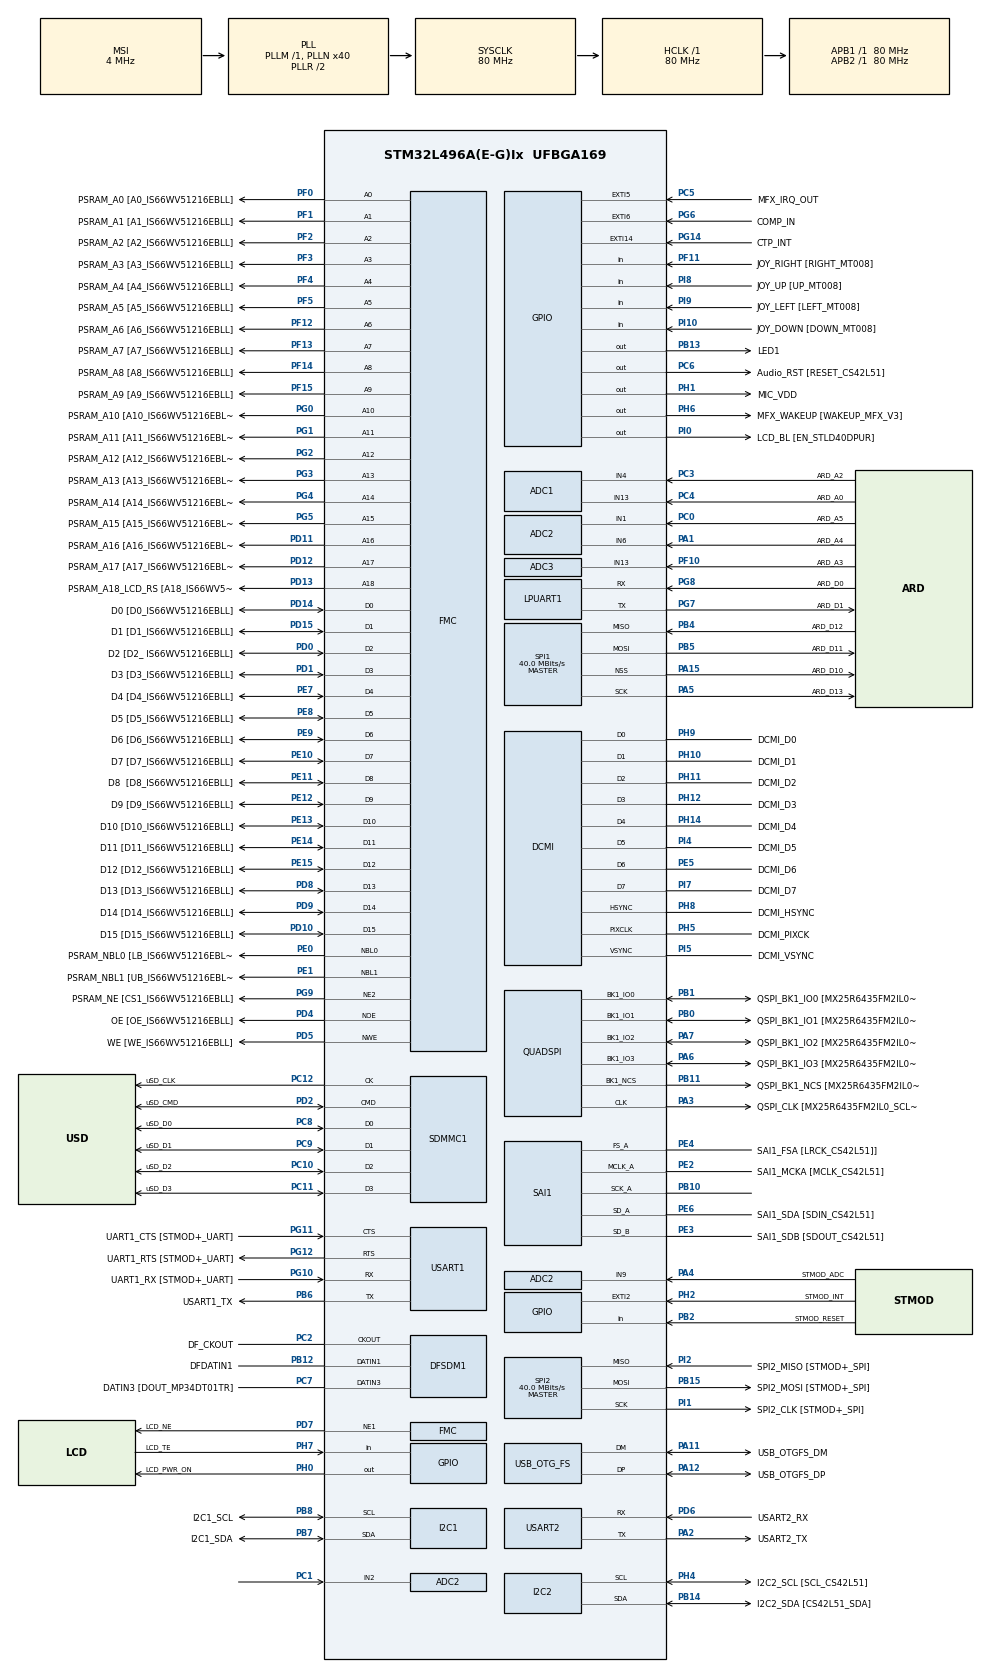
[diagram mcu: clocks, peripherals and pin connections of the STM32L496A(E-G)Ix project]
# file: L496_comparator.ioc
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ADC1.Channel-0\#ChannelRegularConversion=ADC_CHANNEL_4
ADC1.NbrOfConversionFlag=1
ADC1.OffsetNumber-0\#ChannelRegularConversion=ADC_OFFSET_NONE
ADC1.Rank-0\#ChannelRegularConversion=1
ADC1.SamplingTime-0\#ChannelRegularConversion=ADC_SAMPLETIME_2CYCLES_5
ADC1.master=1
ADC2.Channel-0\#ChannelRegularConversion=ADC_CHANNEL_9
ADC2.NbrOfConversionFlag=1
ADC2.OffsetNumber-0\#ChannelRegularConversion=ADC_OFFSET_NONE
ADC2.Rank-0\#ChannelRegularConversion=1
ADC2.SamplingTime-0\#ChannelRegularConversion=ADC_SAMPLETIME_2CYCLES_5
ADC3.Channel-0\#ChannelRegularConversion=ADC_CHANNEL_13
ADC3.NbrOfConversionFlag=1
ADC3.OffsetNumber-0\#ChannelRegularConversion=ADC_OFFSET_NONE
ADC3.Rank-0\#ChannelRegularConversion=1
ADC3.SamplingTime-0\#ChannelRegularConversion=ADC_SAMPLETIME_2CYCLES_5
DCMI.JPEGMode=DCMI_JPEG_DISABLE
I2C1.Timing=0x10909CEC
I2C2.Timing=0x10909CEC
Mcu.Family=STM32L4
Mcu.Name=STM32L496A(E-G)Ix
Mcu.Package=UFBGA169
NVIC.EXTI9_5_IRQn=true\:0\:0\:false\:false\:true\:true\:true
NVIC.OTG_FS_IRQn=true\:0\:0\:false\:false\:true\:true\:true
NVIC.PriorityGroup=NVIC_PRIORITYGROUP_4
NVIC.TIM2_IRQn=true\:0\:0\:false\:false\:true\:true\:true
PA0.GPIO_Label=STMOD_PWM
PA0.Mode=SYS_WakeUp0
PA0.Signal=SYS_WKUP1
PA1.GPIO_Label=ARD_A4
PA1.Signal=ADCx_IN6
PA10.GPIO_Label=USB_OTGFS_ID
PA10.Signal=USB_OTG_FS_ID
PA11.GPIO_Label=USB_OTGFS_DM
PA11.Mode=Device_Only
PA11.Signal=USB_OTG_FS_DM
PA12.GPIO_Label=USB_OTGFS_DP
PA12.Mode=Device_Only
PA12.Signal=USB_OTG_FS_DP
PA13\ (JTMS/SWDIO).GPIO_Label=SWDIO
PA13\ (JTMS/SWDIO).Mode=Serial_Wire
PA13\ (JTMS/SWDIO).Signal=SYS_JTMS-SWDIO
PA14\ (JTCK/SWCLK).GPIO_Label=SWCLK
PA14\ (JTCK/SWCLK).Mode=Serial_Wire
PA14\ (JTCK/SWCLK).Signal=SYS_JTCK-SWCLK
PA15\ (JTDI).GPIO_Label=ARD_D10
PA15\ (JTDI).Mode=NSS_Signal_Hard_Output
PA15\ (JTDI).Signal=SPI1_NSS
PA2.GPIO_Label=USART2_TX
PA2.Mode=Asynchronous
PA2.Signal=USART2_TX
PA3.GPIO_Label=QSPI_CLK [MX25R6435FM2IL0_SCLK]
PA3.Mode=Single Bank 1
PA3.Signal=QUADSPI_CLK
PA4.GPIO_Label=STMOD_ADC
PA4.Signal=ADCx_IN9
PA5.GPIO_Label=ARD_D13
PA5.Mode=Full_Duplex_Master
PA5.Signal=SPI1_SCK
PA6.GPIO_Label=QSPI_BK1_IO3 [MX25R6435FM2IL0_SIO3]
PA6.Mode=Single Bank 1
PA6.Signal=QUADSPI_BK1_IO3
PA7.GPIO_Label=QSPI_BK1_IO2 [MX25R6435FM2IL0_SIO2]
PA7.Mode=Single Bank 1
PA7.Signal=QUADSPI_BK1_IO2
PA8.GPIO_Label=DCMI_CLK
PA8.Signal=LPTIM2_OUT
PA9.GPIO_Label=USB_OTGFS_VBUS
PA9.Signal=USB_OTG_FS_VBUS
PB0.GPIO_Label=QSPI_BK1_IO1 [MX25R6435FM2IL0_SIO1]
PB0.Mode=Single Bank 1
PB0.Signal=QUADSPI_BK1_IO1
PB1.GPIO_Label=QSPI_BK1_IO0 [MX25R6435FM2IL0_SIO0]
PB1.Mode=Single Bank 1
PB1.Signal=QUADSPI_BK1_IO0
PB10.Mode=SAI_A_MasterWithClock
PB10.Signal=SAI1_SCK_A
PB11.GPIO_Label=QSPI_BK1_NCS [MX25R6435FM2IL0_CS]
PB11.Mode=Single Bank 1
PB11.Signal=QUADSPI_BK1_NCS
PB12.GPIO_Label=DFDATIN1
PB12.Signal=S_DATAIN1DFSDM1
PB13.GPIO_Label=LED1
PB13.GPIO_ModeDefaultOutputPP=GPIO_MODE_OUTPUT_OD
PB13.GPIO_PuPd=GPIO_NOPULL
PB13.Signal=GPIO_Output
PB14.GPIO_Label=I2C2_SDA [CS42L51_SDA]
PB14.Mode=I2C
PB14.Signal=I2C2_SDA
PB15.GPIO_Label=SPI2_MOSI [STMOD+_SPI]
PB15.Mode=Full_Duplex_Master
PB15.Signal=SPI2_MOSI
PB2.GPIO_Label=STMOD_RESET
PB2.Signal=GPIO_Input
PB3\ (JTDO/TRACESWO).GPIO_Label=SWO
PB3\ (JTDO/TRACESWO).Signal=SYS_JTDO-SWO
PB4\ (NJTRST).GPIO_Label=ARD_D12
PB4\ (NJTRST).Mode=Full_Duplex_Master
PB4\ (NJTRST).Signal=SPI1_MISO
PB5.GPIO_Label=ARD_D11
PB5.Mode=Full_Duplex_Master
PB5.Signal=SPI1_MOSI
PB6.GPIO_Label=USART1_TX
PB6.Mode=Asynchronous
PB6.Signal=USART1_TX
PB7.GPIO_Label=I2C1_SDA
PB7.Mode=I2C
PB7.Signal=I2C1_SDA
PB8.GPIO_Label=I2C1_SCL
PB8.Mode=I2C
PB8.Signal=I2C1_SCL
PB9.GPIO_Label=ARD_D5
PB9.Signal=S_TIM4_CH4
PC0.GPIO_Label=ARD_A5
PC0.Signal=ADCx_IN1
PC1.Signal=ADCx_IN2
PC10.GPIO_Label=uSD_D2
PC10.Mode=SD_4_bits_Wide_bus
PC10.Signal=SDMMC1_D2
PC11.GPIO_Label=uSD_D3
PC11.Mode=SD_4_bits_Wide_bus
PC11.Signal=SDMMC1_D3
PC12.GPIO_Label=uSD_CLK
PC12.Mode=SD_4_bits_Wide_bus
PC12.Signal=SDMMC1_CK
PC13.GPIO_Label=JOY_SEL [Selection_MT008]
PC13.Mode=SYS_WakeUp1
PC13.Signal=SYS_WKUP2
PC14-OSC32_IN\ (PC14).Mode=LSE-External-Oscillator
PC14-OSC32_IN\ (PC14).Signal=RCC_OSC32_IN
PC15-OSC32_OUT\ (PC15).Mode=LSE-External-Oscillator
PC15-OSC32_OUT\ (PC15).Signal=RCC_OSC32_OUT
PC2.GPIO_Label=DF_CKOUT
PC2.Signal=S_CKOUTDFSDM1
PC3.GPIO_Label=ARD_A2
PC3.Signal=ADCx_IN4
PC4.GPIO_Label=ARD_A0
PC4.Signal=ADCx_IN13
PC5.GPIO_Label=MFX_IRQ_OUT
PC5.Signal=GPXTI5
PC6.GPIO_Label=Audio_RST [RESET_CS42L51]
PC6.Signal=GPIO_Output
PC7.GPIO_Label=DATIN3 [DOUT_MP34DT01TR]
PC7.Signal=S_DATAIN3DFSDM1
PC8.GPIO_Label=uSD_D0
PC8.Mode=SD_4_bits_Wide_bus
PC8.Signal=SDMMC1_D0
PC9.GPIO_Label=uSD_D1
PC9.Mode=SD_4_bits_Wide_bus
PC9.Signal=SDMMC1_D1
PD0.GPIO_Label=D2 [D2_ IS66WV51216EBLL]
PD0.Signal=FMC_D2_DA2
PD1.GPIO_Label=D3 [D3_IS66WV51216EBLL]
PD1.Signal=FMC_D3_DA3
PD10.GPIO_Label=D15 [D15_IS66WV51216EBLL]
PD10.Signal=FMC_D15_DA15
PD11.GPIO_Label=PSRAM_A16 [A16_IS66WV51216EBLL]
PD11.Signal=FMC_A16_CLE
PD12.GPIO_Label=PSRAM_A17 [A17_IS66WV51216EBLL]
PD12.Signal=FMC_A17_ALE
PD13.GPIO_Label=PSRAM_A18_LCD_RS [A18_IS66WV51216EBLL]
PD13.Signal=FMC_A18
PD14.GPIO_Label=D0 [D0_IS66WV51216EBLL]
PD14.Signal=FMC_D0_DA0
PD15.GPIO_Label=D1 [D1_IS66WV51216EBLL]
PD15.Signal=FMC_D1_DA1
PD2.GPIO_Label=uSD_CMD
PD2.Mode=SD_4_bits_Wide_bus
PD2.Signal=SDMMC1_CMD
PD4.GPIO_Label=OE [OE_IS66WV51216EBLL]
PD4.Signal=FMC_NOE
PD5.GPIO_Label=WE [WE_IS66WV51216EBLL]
PD5.Signal=FMC_NWE
PD6.GPIO_Label=USART2_RX
PD6.Mode=Asynchronous
PD6.Signal=USART2_RX
PD7.GPIO_Label=LCD_NE
PD7.Mode=NorPsramChipSelect1_2
PD7.Signal=FMC_NE1
PD8.GPIO_Label=D13 [D13_IS66WV51216EBLL]
PD8.Signal=FMC_D13_DA13
PD9.GPIO_Label=D14 [D14_IS66WV51216EBLL]
PD9.Signal=FMC_D14_DA14
PE0.GPIO_Label=PSRAM_NBL0 [LB_IS66WV51216EBLL]
PE0.Signal=FMC_NBL0
PE1.GPIO_Label=PSRAM_NBL1 [UB_IS66WV51216EBLL]
PE1.Signal=FMC_NBL1
PE10.GPIO_Label=D7 [D7_IS66WV51216EBLL]
PE10.Signal=FMC_D7_DA7
PE11.GPIO_Label=D8  [D8_IS66WV51216EBLL]
PE11.Signal=FMC_D8_DA8
PE12.GPIO_Label=D9 [D9_IS66WV51216EBLL]
PE12.Signal=FMC_D9_DA9
PE13.GPIO_Label=D10 [D10_IS66WV51216EBLL]
PE13.Signal=FMC_D10_DA10
PE14.GPIO_Label=D11 [D11_IS66WV51216EBLL]
PE14.Signal=FMC_D11_DA11
PE15.GPIO_Label=D12 [D12_IS66WV51216EBLL]
PE15.Signal=FMC_D12_DA12
PE2.GPIO_Label=SAI1_MCKA [MCLK_CS42L51]
PE2.Mode=SAI_A_MasterWithClock
PE2.Signal=SAI1_MCLK_A
PE3.GPIO_Label=SAI1_SDB [SDOUT_CS42L51]
PE3.Mode=SAI_B_SyncSlave
PE3.Signal=SAI1_SD_B
PE4.GPIO_Label=SAI1_FSA [LRCK_CS42L51]]
PE4.Mode=SAI_A_MasterWithClock
PE4.Signal=SAI1_FS_A
PE5.GPIO_Label=DCMI_D6
PE5.Mode=Slave_8_bits_External_Synchro
PE5.Signal=DCMI_D6
PE6.GPIO_Label=SAI1_SDA [SDIN_CS42L51]
PE6.Mode=SAI_A_MasterWithClock
PE6.Signal=SAI1_SD_A
PE7.GPIO_Label=D4 [D4_IS66WV51216EBLL]
PE7.Signal=FMC_D4_DA4
PE8.GPIO_Label=D5 [D5_IS66WV51216EBLL]
PE8.Signal=FMC_D5_DA5
PE9.GPIO_Label=D6 [D6_IS66WV51216EBLL]
PE9.Signal=FMC_D6_DA6
PF0.GPIO_Label=PSRAM_A0 [A0_IS66WV51216EBLL]
PF0.Signal=FMC_A0
PF1.GPIO_Label=PSRAM_A1 [A1_IS66WV51216EBLL]
PF1.Signal=FMC_A1
PF10.GPIO_Label=ARD_A3
PF10.Mode=IN13-Single-Ended
PF10.Signal=ADC3_IN13
PF11.GPIO_Label=JOY_RIGHT [RIGHT_MT008]
PF11.GPIO_PuPd=GPIO_PULLDOWN
PF11.Signal=GPIO_Input
PF12.GPIO_Label=PSRAM_A6 [A6_IS66WV51216EBLL]
PF12.Signal=FMC_A6
PF13.GPIO_Label=PSRAM_A7 [A7_IS66WV51216EBLL]
PF13.Signal=FMC_A7
PF14.GPIO_Label=PSRAM_A8 [A8_IS66WV51216EBLL]
PF14.Signal=FMC_A8
PF15.GPIO_Label=PSRAM_A9 [A9_IS66WV51216EBLL]
PF15.Signal=FMC_A9
PF2.GPIO_Label=PSRAM_A2 [A2_IS66WV51216EBLL]
PF2.Signal=FMC_A2
PF3.GPIO_Label=PSRAM_A3 [A3_IS66WV51216EBLL]
PF3.Signal=FMC_A3
PF4.GPIO_Label=PSRAM_A4 [A4_IS66WV51216EBLL]
PF4.Signal=FMC_A4
PF5.GPIO_Label=PSRAM_A5 [A5_IS66WV51216EBLL]
PF5.Signal=FMC_A5
PG0.GPIO_Label=PSRAM_A10 [A10_IS66WV51216EBLL]
PG0.Signal=FMC_A10
PG1.GPIO_Label=PSRAM_A11 [A11_IS66WV51216EBLL]
PG1.Signal=FMC_A11
PG10.GPIO_Label=UART1_RX [STMOD+_UART]
PG10.Mode=Asynchronous
PG10.Signal=USART1_RX
PG11.GPIO_Label=UART1_CTS [STMOD+_UART]
PG11.Mode=CTS_RTS
PG11.Signal=USART1_CTS
PG12.GPIO_Label=UART1_RTS [STMOD+_UART]
PG12.Mode=CTS_RTS
PG12.Signal=USART1_RTS
PG14.GPIO_Label=CTP_INT
PG14.Signal=GPXTI14
PG2.GPIO_Label=PSRAM_A12 [A12_IS66WV51216EBLL]
PG2.Signal=FMC_A12
PG3.GPIO_Label=PSRAM_A13 [A13_IS66WV51216EBLL]
PG3.Signal=FMC_A13
PG4.GPIO_Label=PSRAM_A14 [A14_IS66WV51216EBLL]
PG4.Signal=FMC_A14
PG5.GPIO_Label=PSRAM_A15 [A15_IS66WV51216EBLL]
PG5.Signal=FMC_A15
PG6.GPIO_Label=COMP_IN
PG6.GPIO_ModeDefaultEXTI=GPIO_MODE_IT_RISING_FALLING
PG6.Signal=GPXTI6
PG7.GPIO_Label=ARD_D1
PG7.Mode=Asynchronous
PG7.Signal=LPUART1_TX
PG8.GPIO_Label=ARD_D0
PG8.Mode=Asynchronous
PG8.Signal=LPUART1_RX
PG9.GPIO_Label=PSRAM_NE [CS1_IS66WV51216EBLL]
PG9.Mode=NorPsramChipSelect2_1
PG9.Signal=FMC_NE2
PH0-OSC_IN\ (PH0).GPIO_Label=LCD_PWR_ON
PH0-OSC_IN\ (PH0).Signal=GPIO_Output
PH1-OSC_OUT\ (PH1).GPIO_Label=MIC_VDD
PH1-OSC_OUT\ (PH1).Signal=GPIO_Output
PH10.GPIO_Label=DCMI_D1
PH10.Mode=Slave_8_bits_External_Synchro
PH10.Signal=DCMI_D1
PH11.GPIO_Label=DCMI_D2
PH11.Mode=Slave_8_bits_External_Synchro
PH11.Signal=DCMI_D2
PH12.GPIO_Label=DCMI_D3
PH12.Mode=Slave_8_bits_External_Synchro
PH12.Signal=DCMI_D3
PH13.GPIO_Label=ARD_D9
PH13.Signal=TIM8_CH1N
PH14.GPIO_Label=DCMI_D4
PH14.Mode=Slave_8_bits_External_Synchro
PH14.Signal=DCMI_D4
PH15.GPIO_Label=ARD_D3
PH15.Signal=TIM8_CH3N
PH2.GPIO_Label=STMOD_INT
PH2.Signal=GPXTI2
PH4.GPIO_Label=I2C2_SCL [SCL_CS42L51]
PH4.Mode=I2C
PH4.Signal=I2C2_SCL
PH5.GPIO_Label=DCMI_PIXCK
PH5.Mode=Slave_8_bits_External_Synchro
PH5.Signal=DCMI_PIXCLK
PH6.GPIO_Label=MFX_WAKEUP [WAKEUP_MFX_V3]
PH6.Signal=GPIO_Output
PH7.GPIO_Label=LCD_TE
PH7.Signal=GPIO_Input
PH8.GPIO_Label=DCMI_HSYNC
PH8.Mode=Slave_8_bits_External_Synchro
PH8.Signal=DCMI_HSYNC
PH9.GPIO_Label=DCMI_D0
PH9.Mode=Slave_8_bits_External_Synchro
PH9.Signal=DCMI_D0
PI0.GPIO_Label=LCD_BL [EN_STLD40DPUR]
PI0.Signal=GPIO_Output
PI1.GPIO_Label=SPI2_CLK [STMOD+_SPI]
PI1.Mode=Full_Duplex_Master
PI1.Signal=SPI2_SCK
PI10.GPIO_Label=JOY_DOWN [DOWN_MT008]
PI10.GPIO_PuPd=GPIO_PULLDOWN
PI10.Signal=GPIO_Input
PI2.GPIO_Label=SPI2_MISO [STMOD+_SPI]
PI2.Mode=Full_Duplex_Master
PI2.Signal=SPI2_MISO
PI4.GPIO_Label=DCMI_D5
PI4.Mode=Slave_8_bits_External_Synchro
PI4.Signal=DCMI_D5
PI5.GPIO_Label=DCMI_VSYNC
PI5.Mode=Slave_8_bits_External_Synchro
PI5.Signal=DCMI_VSYNC
PI6.GPIO_Label=ARD_D6
PI6.Signal=S_TIM8_CH2
PI7.GPIO_Label=DCMI_D7
PI7.Mode=Slave_8_bits_External_Synchro
PI7.Signal=DCMI_D7
PI8.GPIO_Label=JOY_UP [UP_MT008]
PI8.GPIO_PuPd=GPIO_PULLDOWN
PI8.Signal=GPIO_Input
PI9.GPIO_Label=JOY_LEFT [LEFT_MT008]
PI9.GPIO_PuPd=GPIO_PULLDOWN
PI9.Signal=GPIO_Input
ProjectManager.HeapSize=0x200
ProjectManager.StackSize=0x400
ProjectManager.TargetToolchain=STM32CubeIDE
QUADSPI.ClockPrescaler=2
QUADSPI.FifoThreshold=4
QUADSPI.FlashSize=23
QUADSPI.SampleShifting=QSPI_SAMPLE_SHIFTING_HALFCYCLE
RCC.ADCFreq_Value=48000000
RCC.AHBFreq_Value=80000000
RCC.APB1Freq_Value=80000000
RCC.APB1TimFreq_Value=80000000
RCC.APB2Freq_Value=80000000
RCC.APB2TimFreq_Value=80000000
RCC.CortexFreq_Value=80000000
RCC.HCLKFreq_Value=80000000
RCC.HSE_VALUE=8000000
RCC.HSI48_VALUE=48000000
RCC.HSI_VALUE=16000000
RCC.MSI_VALUE=4000000
RCC.PLLN=40
RCC.PLLSAI1N=24
RCC.SYSCLKFreq_VALUE=80000000
RCC.SYSCLKSource=RCC_SYSCLKSOURCE_PLLCLK
RCC.USBFreq_Value=48000000
RCC.VCOOutputFreq_Value=160000000
SAI1.ErrorAudioFreq-SAI_A_MasterWithClock=-2.34 %
SAI1.Instance-SAI_A_MasterWithClock=SAI$Index_Block_A
SAI1.Instance-SAI_B_SyncSlave=SAI$Index_Block_B
SAI1.MClockEnable-SAI_A_MasterWithClock=SAI_MASTERCLOCK_ENABLE
SAI1.RealAudioFreq-SAI_A_MasterWithClock=187.5 KHz
SAI1.VirtualMode-SAI_A_MasterWithClock=VM_MASTER
SAI1.VirtualMode-SAI_B_SyncSlave=VM_SLAVE
SH.ADCx_IN1.0=ADC2_IN1,IN1-Single-Ended
SH.ADCx_IN13.0=ADC1_IN13,IN13-Single-Ended
SH.ADCx_IN2.0=ADC2_IN2,IN2-Single-Ended
SH.ADCx_IN4.0=ADC1_IN4,IN4-Single-Ended
SH.ADCx_IN6.0=ADC2_IN6,IN6-Single-Ended
SH.ADCx_IN9.0=ADC2_IN9,IN9-Single-Ended
SH.FMC_A0.0=FMC_A0,18b-a1
SH.FMC_A1.0=FMC_A1,18b-a1
SH.FMC_A10.0=FMC_A10,18b-a1
SH.FMC_A11.0=FMC_A11,18b-a1
SH.FMC_A12.0=FMC_A12,18b-a1
SH.FMC_A13.0=FMC_A13,18b-a1
SH.FMC_A14.0=FMC_A14,18b-a1
SH.FMC_A15.0=FMC_A15,18b-a1
SH.FMC_A16_CLE.0=FMC_A16,18b-a1
SH.FMC_A17_ALE.0=FMC_A17,18b-a1
SH.FMC_A18.0=FMC_A18,A18_2
SH.FMC_A2.0=FMC_A2,18b-a1
SH.FMC_A3.0=FMC_A3,18b-a1
SH.FMC_A4.0=FMC_A4,18b-a1
SH.FMC_A5.0=FMC_A5,18b-a1
SH.FMC_A6.0=FMC_A6,18b-a1
SH.FMC_A7.0=FMC_A7,18b-a1
SH.FMC_A8.0=FMC_A8,18b-a1
SH.FMC_A9.0=FMC_A9,18b-a1
SH.FMC_D0_DA0.0=FMC_D0,16b-d1
SH.FMC_D0_DA0.1=FMC_D0,16b-d2
SH.FMC_D10_DA10.0=FMC_D10,16b-d1
SH.FMC_D10_DA10.1=FMC_D10,16b-d2
SH.FMC_D11_DA11.0=FMC_D11,16b-d1
SH.FMC_D11_DA11.1=FMC_D11,16b-d2
SH.FMC_D12_DA12.0=FMC_D12,16b-d1
SH.FMC_D12_DA12.1=FMC_D12,16b-d2
SH.FMC_D13_DA13.0=FMC_D13,16b-d1
SH.FMC_D13_DA13.1=FMC_D13,16b-d2
SH.FMC_D14_DA14.0=FMC_D14,16b-d1
SH.FMC_D14_DA14.1=FMC_D14,16b-d2
SH.FMC_D15_DA15.0=FMC_D15,16b-d1
SH.FMC_D15_DA15.1=FMC_D15,16b-d2
SH.FMC_D1_DA1.0=FMC_D1,16b-d1
SH.FMC_D1_DA1.1=FMC_D1,16b-d2
SH.FMC_D2_DA2.0=FMC_D2,16b-d1
SH.FMC_D2_DA2.1=FMC_D2,16b-d2
SH.FMC_D3_DA3.0=FMC_D3,16b-d1
SH.FMC_D3_DA3.1=FMC_D3,16b-d2
SH.FMC_D4_DA4.0=FMC_D4,16b-d1
SH.FMC_D4_DA4.1=FMC_D4,16b-d2
SH.FMC_D5_DA5.0=FMC_D5,16b-d1
SH.FMC_D5_DA5.1=FMC_D5,16b-d2
SH.FMC_D6_DA6.0=FMC_D6,16b-d1
SH.FMC_D6_DA6.1=FMC_D6,16b-d2
SH.FMC_D7_DA7.0=FMC_D7,16b-d1
SH.FMC_D7_DA7.1=FMC_D7,16b-d2
SH.FMC_D8_DA8.0=FMC_D8,16b-d1
SH.FMC_D8_DA8.1=FMC_D8,16b-d2
SH.FMC_D9_DA9.0=FMC_D9,16b-d1
SH.FMC_D9_DA9.1=FMC_D9,16b-d2
SH.FMC_NBL0.0=FMC_NBL0,2ByteEnable1
SH.FMC_NBL1.0=FMC_NBL1,2ByteEnable1
SH.FMC_NOE.0=FMC_NOE,Sram1
SH.FMC_NOE.1=FMC_NOE,Lcd2
SH.FMC_NWE.0=FMC_NWE,Sram1
SH.FMC_NWE.1=FMC_NWE,Lcd2
SH.S_CKOUTDFSDM1.0=DFSDM1_CKOUT,PDM_SPI_Input_from_ch23_and_Internal_Clock
SH.S_CKOUTDFSDM1.1=DFSDM1_CKOUT,PDM_SPI_input_from_ch1_and_internal_clock
SH.S_DATAIN1DFSDM1.0=DFSDM1_DATIN1,PDM_SPI_input_from_ch1_and_internal_clock
SH.S_DATAIN3DFSDM1.0=DFSDM1_DATIN3,PDM_SPI_Input_from_ch23_and_Internal_Clock
SH.S_TIM4_CH4.0=TIM4_CH4
SH.S_TIM8_CH2.0=TIM8_CH2
SPI1.CalculateBaudRate=40.0 MBits/s
SPI1.Direction=SPI_DIRECTION_2LINES
SPI1.Mode=SPI_MODE_MASTER
SPI1.VirtualNSS=VM_NSSHARD
SPI1.VirtualType=VM_MASTER
SPI2.CalculateBaudRate=40.0 MBits/s
SPI2.Direction=SPI_DIRECTION_2LINES
SPI2.Mode=SPI_MODE_MASTER
SPI2.VirtualType=VM_MASTER
TIM2.Period=1000-1
TIM2.Prescaler=80-1
USART1.VirtualMode-Asynchronous=VM_ASYNC
USART2.VirtualMode-Asynchronous=VM_ASYNC
USB_DEVICE.CLASS_NAME_FS=CDC
USB_DEVICE.VirtualMode=Cdc
USB_DEVICE.VirtualModeFS=Cdc_FS
USB_OTG_FS.VirtualMode=Device_Only
VP_TIM2_VS_ClockSourceINT.Mode=Internal
VP_USB_DEVICE_VS_USB_DEVICE_CDC_FS.Mode=CDC_FS
board=STM32L496G-DISCO

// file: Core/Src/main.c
/* USER CODE BEGIN Header */
/**
  ******************************************************************************
  * @file           : main.c
  * @brief          : Main program body
  ******************************************************************************
  * @attention
  *
  * <h2><center>&copy; Copyright (c) 2021 STMicroelectronics.
  * All rights reserved.</center></h2>
  *
  * This software component is licensed by ST under Ultimate Liberty license
  * SLA0044, the "License"; You may not use this file except in compliance with
  * the License. You may obtain a copy of the License at:
  *                             www.st.com/SLA0044
  *
  ******************************************************************************
  */
/* USER CODE END Header */
#include "main.h"
#include "adc.h"
#include "dcmi.h"
#include "dfsdm.h"
#include "i2c.h"
#include "usart.h"
#include "quadspi.h"
#include "sai.h"
#include "sdmmc.h"
#include "spi.h"
#include "tim.h"
#include "usb_device.h"
#include "gpio.h"
#include "fmc.h"

/* USER CODE BEGIN Includes */
#include "stm32l4xx_hal_uart.h"
#include <stdio.h>
#include <string.h>

#include "stm32l496g_discovery_lcd.h"
#include "fonts.h"
/* USER CODE END Includes */

/* USER CODE BEGIN PV */
uint16_t timeCounting = 0;
uint16_t count = 0;

uint16_t frequency;
uint16_t frequency_old = 0;
double speed;
char frequency_str[100] = "";
char speed_str[100] = "";
/* USER CODE END PV */

void SystemClock_Config(void);

int main(void)
{

  /* MCU Configuration--------------------------------------------------------*/

  /* Reset of all peripherals, Initializes the Flash interface and the Systick. */
  HAL_Init();

  /* Configure the system clock */
  SystemClock_Config();

  /* Initialize all configured peripherals */
  MX_GPIO_Init();
  MX_ADC1_Init();
  MX_ADC2_Init();
  MX_ADC3_Init();
  MX_DCMI_Init();
  MX_DFSDM1_Init();
  MX_FMC_Init();
  MX_I2C1_Init();
  MX_I2C2_Init();
  MX_LPUART1_UART_Init();
  MX_USART1_UART_Init();
  MX_USART2_UART_Init();
  MX_QUADSPI_Init();
  MX_SAI1_Init();
  MX_SDMMC1_SD_Init();
  MX_SPI1_Init();
  MX_SPI2_Init();
  MX_USB_DEVICE_Init();
  MX_TIM2_Init();
  /* USER CODE BEGIN 2 */
  HAL_TIM_Base_Start_IT(&htim2);

  BSP_LCD_Init();
  BSP_LCD_Clear(LCD_COLOR_WHITE);
  BSP_LCD_SetFont(&Font20);
  /* USER CODE END 2 */

  /* Infinite loop */
  while (1)
  {

    /* USER CODE BEGIN 3 */
//	if (timeCounting >= 0)
//	{
//	  HAL_TIM_Base_Start_IT(&htim2);
//	}
	if (timeCounting == 500)
	{
	  HAL_TIM_Base_Stop_IT(&htim2);
	  frequency = (count / 2) / 0.5;
	  speed = frequency / 19.49 / 3.6;
	  sprintf(frequency_str, "%d", frequency);
	  sprintf(speed_str, "%.3f", speed);
//	  HAL_UART_Transmit(&huart2, (uint8_t*) frequency_str, sizeof(frequency_str), 0xffff);
//	  HAL_UART_Transmit(&huart2, (uint8_t*) " \n", sizeof(" \n"), 0xffff);
	  if (frequency_old != frequency)
	  {
		BSP_LCD_Clear(LCD_COLOR_WHITE);

		frequency_old = frequency;
	  }

	  BSP_LCD_DisplayStringAtLine(0, "Signal frequency:");
	  BSP_LCD_DisplayStringAtLine(6, "Object speed:");
	  BSP_LCD_DisplayStringAt(0, 60, frequency_str, LEFT_MODE);
	  BSP_LCD_DisplayStringAt(0, 180, speed_str, LEFT_MODE);
	  BSP_LCD_DisplayStringAt(100, 180, "m/s", LEFT_MODE);

	  timeCounting = 0;
	  count = 0;
	  HAL_TIM_Base_Start_IT(&htim2);
	}
  }
  /* USER CODE END 3 */
}

void SystemClock_Config(void)
{
  RCC_OscInitTypeDef RCC_OscInitStruct = {0};
  RCC_ClkInitTypeDef RCC_ClkInitStruct = {0};
  RCC_PeriphCLKInitTypeDef PeriphClkInit = {0};

  /** Configure LSE Drive Capability
  */
  HAL_PWR_EnableBkUpAccess();
  __HAL_RCC_LSEDRIVE_CONFIG(RCC_LSEDRIVE_LOW);
  /** Initializes the RCC Oscillators according to the specified parameters
  * in the RCC_OscInitTypeDef structure.
  */
  RCC_OscInitStruct.OscillatorType = RCC_OSCILLATORTYPE_LSE|RCC_OSCILLATORTYPE_MSI;
  RCC_OscInitStruct.LSEState = RCC_LSE_ON;
  RCC_OscInitStruct.MSIState = RCC_MSI_ON;
  RCC_OscInitStruct.MSICalibrationValue = 0;
  RCC_OscInitStruct.MSIClockRange = RCC_MSIRANGE_6;
  RCC_OscInitStruct.PLL.PLLState = RCC_PLL_ON;
  RCC_OscInitStruct.PLL.PLLSource = RCC_PLLSOURCE_MSI;
  RCC_OscInitStruct.PLL.PLLM = 1;
  RCC_OscInitStruct.PLL.PLLN = 40;
  RCC_OscInitStruct.PLL.PLLP = RCC_PLLP_DIV2;
  RCC_OscInitStruct.PLL.PLLQ = RCC_PLLQ_DIV2;
  RCC_OscInitStruct.PLL.PLLR = RCC_PLLR_DIV2;
  if (HAL_RCC_OscConfig(&RCC_OscInitStruct) != HAL_OK)
  {
    Error_Handler();
  }
  /** Initializes the CPU, AHB and APB buses clocks
  */
  RCC_ClkInitStruct.ClockType = RCC_CLOCKTYPE_HCLK|RCC_CLOCKTYPE_SYSCLK
                              |RCC_CLOCKTYPE_PCLK1|RCC_CLOCKTYPE_PCLK2;
  RCC_ClkInitStruct.SYSCLKSource = RCC_SYSCLKSOURCE_PLLCLK;
  RCC_ClkInitStruct.AHBCLKDivider = RCC_SYSCLK_DIV1;
  RCC_ClkInitStruct.APB1CLKDivider = RCC_HCLK_DIV1;
  RCC_ClkInitStruct.APB2CLKDivider = RCC_HCLK_DIV1;

  if (HAL_RCC_ClockConfig(&RCC_ClkInitStruct, FLASH_LATENCY_4) != HAL_OK)
  {
    Error_Handler();
  }
  PeriphClkInit.PeriphClockSelection = RCC_PERIPHCLK_USART1|RCC_PERIPHCLK_USART2
                              |RCC_PERIPHCLK_LPUART1|RCC_PERIPHCLK_SAI1
                              |RCC_PERIPHCLK_I2C1|RCC_PERIPHCLK_I2C2
                              |RCC_PERIPHCLK_DFSDM1|RCC_PERIPHCLK_USB
                              |RCC_PERIPHCLK_SDMMC1|RCC_PERIPHCLK_ADC;
  PeriphClkInit.Usart1ClockSelection = RCC_USART1CLKSOURCE_PCLK2;
  PeriphClkInit.Usart2ClockSelection = RCC_USART2CLKSOURCE_PCLK1;
  PeriphClkInit.Lpuart1ClockSelection = RCC_LPUART1CLKSOURCE_PCLK1;
  PeriphClkInit.I2c1ClockSelection = RCC_I2C1CLKSOURCE_PCLK1;
  PeriphClkInit.I2c2ClockSelection = RCC_I2C2CLKSOURCE_PCLK1;
  PeriphClkInit.Sai1ClockSelection = RCC_SAI1CLKSOURCE_PLLSAI1;
  PeriphClkInit.AdcClockSelection = RCC_ADCCLKSOURCE_PLLSAI1;
  PeriphClkInit.Dfsdm1ClockSelection = RCC_DFSDM1CLKSOURCE_PCLK;
  PeriphClkInit.UsbClockSelection = RCC_USBCLKSOURCE_PLLSAI1;
  PeriphClkInit.Sdmmc1ClockSelection = RCC_SDMMC1CLKSOURCE_PLLSAI1;
  PeriphClkInit.PLLSAI1.PLLSAI1Source = RCC_PLLSOURCE_MSI;
  PeriphClkInit.PLLSAI1.PLLSAI1M = 1;
  PeriphClkInit.PLLSAI1.PLLSAI1N = 24;
  PeriphClkInit.PLLSAI1.PLLSAI1P = RCC_PLLP_DIV2;
  PeriphClkInit.PLLSAI1.PLLSAI1Q = RCC_PLLQ_DIV2;
  PeriphClkInit.PLLSAI1.PLLSAI1R = RCC_PLLR_DIV2;
  PeriphClkInit.PLLSAI1.PLLSAI1ClockOut = RCC_PLLSAI1_SAI1CLK|RCC_PLLSAI1_48M2CLK
                              |RCC_PLLSAI1_ADC1CLK;
  if (HAL_RCCEx_PeriphCLKConfig(&PeriphClkInit) != HAL_OK)
  {
    Error_Handler();
  }
  /** Configure the main internal regulator output voltage
  */
  if (HAL_PWREx_ControlVoltageScaling(PWR_REGULATOR_VOLTAGE_SCALE1) != HAL_OK)
  {
    Error_Handler();
  }
  /** Enable MSI Auto calibration
  */
  HAL_RCCEx_EnableMSIPLLMode();
}

/* USER CODE BEGIN 4 */
void HAL_TIM_PeriodElapsedCallback(TIM_HandleTypeDef *htim)
{
  if (htim == &htim2)
  {
	timeCounting++;
  }
}

void HAL_GPIO_EXTI_Callback(uint16_t GPIO_Pin)
{
  if (GPIO_Pin == COMP_IN_Pin)
  {
	count++;
  }
}
/* USER CODE END 4 */

void Error_Handler(void)
{
  __disable_irq();
  while (1)
  {
  }
}

/************************ (C) COPYRIGHT STMicroelectronics *****END OF FILE****/
